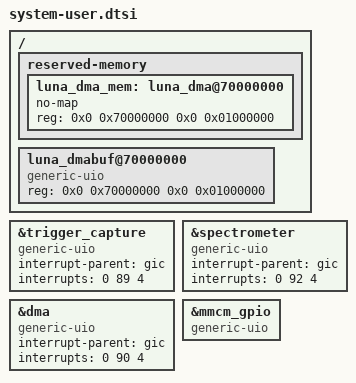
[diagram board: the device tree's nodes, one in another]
/*
 * system-user.dtsi - lunaZCU111 additions to the generated device tree
 *
 * - bootargs are generated by PetaLinux; setup.sh adds
 *   "uio_pdrv_genirq.of_id=generic-uio" via CONFIG_SUBSYSTEM_EXTRA_BOOTARGS
 * - 16 MiB reserved DDR at 0x7000_0000 as the AXI DMA target, exposed as UIO
 * - trigger core, AXI DMA and MMCM GPIO handed to user space (UIO) instead of
 *   the kernel dmaengine / gpio drivers
 * - the RFDC node generated by the DTG (with its "param-list") is left as is;
 *   librfdc/libmetal binds it to uio_pdrv_genirq at run time
 *
 * PL interrupts (pl_ps_irq0 -> GIC SPI 89..): 89 trigger, 90 DMA S2MM, 91 RFDC,
 * 92 spectrometer
 */
/include/ "system-conf.dtsi"
/ {
	reserved-memory {
		#address-cells = <2>;
		#size-cells = <2>;
		ranges;
		luna_dma_mem: luna_dma@70000000 {
			no-map;
			reg = <0x0 0x70000000 0x0 0x01000000>;
		};
	};

	luna_dmabuf@70000000 {
		compatible = "generic-uio";
		reg = <0x0 0x70000000 0x0 0x01000000>;
	};
};

/* trigger / capture core (module reference, see hw/hdl) */
&trigger_capture {
	compatible = "generic-uio";
	interrupt-parent = <&gic>;
	interrupts = <0 89 4>;
};

/* spectrometer on ADC channel 0 (module reference, see hw/hdl) */
&spectrometer {
	compatible = "generic-uio";
	interrupt-parent = <&gic>;
	interrupts = <0 92 4>;
};

/* AXI DMA (S2MM, simple mode) driven from user space */
&dma {
	compatible = "generic-uio";
	interrupt-parent = <&gic>;
	interrupts = <0 90 4>;
	/delete-node/ dma-channel@a0110030;
};

/* AXI GPIO: MMCM reset / lock */
&mmcm_gpio {
	compatible = "generic-uio";
	/delete-property/ gpio-controller;
	/delete-property/ #gpio-cells;
};
